VERSION ""

NS_ :

BS_:

BU_: NJX Third_Party VCU

BO_ 3221225472 VECTOR__INDEPENDENT_SIG_MSG: 0 Vector__XXX
 SG_ DEBUG_zero_suspension_travel : 0|1@1+ (1,0) [0|1] "" Vector__XXX
 SG_ SMU_BTN_external_tsa_btn_presse : 0|1@1+ (1,0) [0|1] "" Vector__XXX
 SG_ SMU_BTN_ami_btn_pressed : 0|1@1+ (1,0) [0|1] "" Vector__XXX
 SG_ SMU_BTN_rst_btn_pressed : 0|1@1+ (1,0) [0|1] "" Vector__XXX
 SG_ TSCD_K6_closed : 0|1@1+ (1,0) [0|1] "" Vector__XXX
 SG_ TSCD_SDC_active : 0|1@1+ (1,0) [0|1] "" Vector__XXX
 SG_ TSCD_SDC_in : 0|1@1+ (1,0) [0|1] "" Vector__XXX
 SG_ TSCD_TS_off : 0|1@1+ (1,0) [0|1] "" Vector__XXX
 SG_ TSCD_air_neg_closed : 0|1@1+ (1,0) [0|1] "" Vector__XXX
 SG_ TSCD_air_pos_closed : 0|1@1+ (1,0) [0|1] "" Vector__XXX
 SG_ TSCD_precharge_finished : 0|1@1+ (1,0) [0|1] "" Vector__XXX
 SG_ TSCD_precharge_relay_closed : 0|1@1+ (1,0) [0|1] "" Vector__XXX
 SG_ VCU_NM_all_active : 0|1@1+ (1,0) [0|1] "" Vector__XXX
 SG_ AMS_error_batt_cv_ct_init : 0|1@1+ (1,0) [0|1] "" Vector__XXX
 SG_ AMS_error_batt_iso_meas_monitor : 0|1@1+ (1,0) [0|1] "" Vector__XXX
 SG_ AMS_error_batt_vit_init : 0|1@1+ (1,0) [0|1] "" Vector__XXX
 SG_ AMS_error_bms_init_1 : 0|1@1+ (1,0) [0|1] "" Vector__XXX
 SG_ AMS_error_bms_init_2 : 0|1@1+ (1,0) [0|1] "" Vector__XXX
 SG_ AMS_error_bms_init_3 : 0|1@1+ (1,0) [0|1] "" Vector__XXX
 SG_ AMS_error_can_init : 0|1@1+ (1,0) [0|1] "" Vector__XXX
 SG_ AMS_error_current_init : 0|1@1+ (1,0) [0|1] "" Vector__XXX
 SG_ AMS_error_cv_ct_rx_monitor : 0|1@1+ (1,0) [0|1] "" Vector__XXX
 SG_ AMS_error_eeprom_rd : 0|1@1+ (1,0) [0|1] "" Vector__XXX
 SG_ AMS_error_eeprom_wr : 0|1@1+ (1,0) [0|1] "" Vector__XXX
 SG_ AMS_error_eio1 : 0|1@1+ (1,0) [0|1] "" Vector__XXX
 SG_ AMS_error_eio2 : 0|1@1+ (1,0) [0|1] "" Vector__XXX
 SG_ AMS_error_fan : 0|1@1+ (1,0) [0|1] "" Vector__XXX
 SG_ AMS_error_lim_cell_minmax_volt : 0|1@1+ (1,0) [0|1] "" Vector__XXX
 SG_ AMS_error_lim_current_1_cont : 0|1@1+ (1,0) [0|1] "" Vector__XXX
 SG_ AMS_error_lim_current_1_max : 0|1@1+ (1,0) [0|1] "" Vector__XXX
 SG_ AMS_error_lim_current_1_pulse : 0|1@1+ (1,0) [0|1] "" Vector__XXX
 SG_ AMS_error_lim_current_2_cont : 0|1@1+ (1,0) [0|1] "" Vector__XXX
 SG_ AMS_error_lim_iso : 0|1@1+ (1,0) [0|1] "" Vector__XXX
 SG_ AMS_error_lim_soc : 0|1@1+ (1,0) [0|1] "" Vector__XXX
 SG_ AMS_error_lim_temp : 0|1@1+ (1,0) [0|1] "" Vector__XXX
 SG_ AMS_error_lim_volt : 0|1@1+ (1,0) [0|1] "" Vector__XXX
 SG_ AMS_error_lim_volt_ext : 0|1@1+ (1,0) [0|1] "" Vector__XXX
 SG_ AMS_error_not_ready : 0|1@1+ (1,0) [0|1] "" Vector__XXX
 SG_ AMS_general_error : 0|1@1+ (1,0) [0|1] "" Vector__XXX
 SG_ AMS_mcu_error : 0|1@1+ (1,0) [0|1] "" Vector__XXX
 SG_ AMS_plaus_error : 0|1@1+ (1,0) [0|1] "" Vector__XXX
 SG_ AMS_realtime_error : 0|1@1+ (1,0) [0|1] "" Vector__XXX
 SG_ AMS_soc : 0|16@1+ (0.01,0) [0|655.35] "%" Vector__XXX
 SG_ SMU_BTN_ami_btn_pressed : 0|1@1+ (1,0) [0|1] "" Vector__XXX
 SG_ SMU_BTN_external_tsa_btn_presse : 0|1@1+ (1,0) [0|1] "" Vector__XXX
 SG_ SMU_BTN_general_error : 0|1@1+ (1,0) [0|1] "" Vector__XXX
 SG_ SMU_BTN_mcu_error : 0|1@1+ (1,0) [0|1] "" Vector__XXX
 SG_ SMU_BTN_plaus_error : 0|1@1+ (1,0) [0|1] "" Vector__XXX
 SG_ SMU_BTN_realtime_error : 0|1@1+ (1,0) [0|1] "" Vector__XXX
 SG_ SMU_BTN_rst_btn_pressed : 0|1@1+ (1,0) [0|1] "" Vector__XXX
 SG_ TSCD_general_error : 0|1@1+ (1,0) [0|1] "" Vector__XXX
 SG_ TSCD_mcu_error : 0|1@1+ (1,0) [0|1] "" Vector__XXX
 SG_ TSCD_plaus_error : 0|1@1+ (1,0) [0|1] "" Vector__XXX
 SG_ TSCD_realtime_error : 0|1@1+ (1,0) [0|1] "" Vector__XXX
 SG_ ISU_AMS_ok : 0|1@1+ (1,0) [0|0] "" Vector__XXX
 SG_ ISU_IMD_ok : 0|1@1+ (1,0) [0|0] "" Vector__XXX
 SG_ ISU_general_error : 0|1@1+ (1,0) [0|1] "" Vector__XXX
 SG_ ISU_mcu_error : 0|1@1+ (1,0) [0|1] "" Vector__XXX
 SG_ ISU_plaus_error : 0|1@1+ (1,0) [0|1] "" Vector__XXX
 SG_ ISU_realtime_error : 0|1@1+ (1,0) [0|1] "" Vector__XXX
 SG_ AMS_i_battery : 0|16@1- (0.01,0) [-327.68|327.67] "A" Vector__XXX
 SG_ AMS_u_battery : 0|16@1+ (0.01,0) [0|655.35] "V" Vector__XXX
 SG_ AMS_temp_avg_stack_1 : 0|8@1+ (0.5,0) [0|127.5] "°C" Vector__XXX
 SG_ AMS_temp_avg_stack_2 : 0|8@1+ (0.5,0) [0|127.5] "°C" Vector__XXX
 SG_ AMS_temp_avg_stack_3 : 0|8@1+ (0.5,0) [0|127.5] "°C" Vector__XXX
 SG_ AMS_temp_avg_stack_4 : 0|8@1+ (0.5,0) [0|127.5] "°C" Vector__XXX
 SG_ AMS_temp_max_stack_1 : 0|8@1+ (0.5,0) [0|127.5] "°C" Vector__XXX
 SG_ AMS_temp_max_stack_2 : 0|8@1+ (0.5,0) [0|127.5] "°C" Vector__XXX
 SG_ AMS_temp_max_stack_3 : 0|8@1+ (0.5,0) [0|127.5] "°C" Vector__XXX
 SG_ AMS_temp_max_stack_4 : 0|8@1+ (0.5,0) [0|127.5] "°C" Vector__XXX
 SG_ AMS_temp_avg_stack_5 : 0|8@1+ (0.5,0) [0|127.5] "°C" Vector__XXX
 SG_ AMS_temp_avg_stack_6 : 0|8@1+ (0.5,0) [0|127.5] "°C" Vector__XXX
 SG_ AMS_temp_avg_stack_7 : 0|8@1+ (0.5,0) [0|127.5] "°C" Vector__XXX
 SG_ AMS_temp_avg_stack_8 : 0|8@1+ (0.5,0) [0|127.5] "°C" Vector__XXX
 SG_ AMS_temp_max_stack_5 : 0|8@1+ (0.5,0) [0|127.5] "°C" Vector__XXX
 SG_ AMS_temp_max_stack_6 : 0|8@1+ (0.5,0) [0|127.5] "°C" Vector__XXX
 SG_ AMS_temp_max_stack_7 : 0|8@1+ (0.5,0) [0|127.5] "°C" Vector__XXX
 SG_ AMS_temp_max_stack_8 : 0|8@1+ (0.5,0) [0|127.5] "°C" Vector__XXX
 SG_ AMS_temp_avg_stack_10 : 0|8@1+ (0.5,0) [0|127.5] "°C" Vector__XXX
 SG_ AMS_temp_avg_stack_11 : 0|8@1+ (0.5,0) [0|127.5] "°C" Vector__XXX
 SG_ AMS_temp_avg_stack_12 : 0|8@1+ (0.5,0) [0|127.5] "°C" Vector__XXX
 SG_ AMS_temp_avg_stack_9 : 0|8@1+ (0.5,0) [0|127.5] "°C" Vector__XXX
 SG_ AMS_temp_max_stack_10 : 0|8@1+ (0.5,0) [0|127.5] "°C" Vector__XXX
 SG_ AMS_temp_max_stack_11 : 0|8@1+ (0.5,0) [0|127.5] "°C" Vector__XXX
 SG_ AMS_temp_max_stack_12 : 0|8@1+ (0.5,0) [0|127.5] "°C" Vector__XXX
 SG_ AMS_temp_max_stack_9 : 0|8@1+ (0.5,0) [0|127.5] "°C" Vector__XXX
 SG_ TSCD_VBAT : 0|16@1+ (0.01,0) [0|655.35] "V" Vector__XXX
 SG_ TSCD_VINT : 0|16@1+ (0.01,0) [0|655.35] "V" Vector__XXX
 SG_ TSCD_VPRE : 0|16@1+ (0.01,0) [0|655.35] "V" Vector__XXX
 SG_ TSCD_precharge_to_ubat : 0|8@1+ (1,0) [0|255] "%" Vector__XXX
 SG_ AngSPoi : 0|16@1- (0.003,0) [-39.999|39.999] "ï¿½" Vector__XXX
 SG_ VelAPoi : 0|16@1- (0.02,0) [0|450] "km/h" Vector__XXX
 SG_ VelXPoi : 0|16@1- (0.02,0) [-450|450] "km/h" Vector__XXX
 SG_ VelYPoi : 0|16@1- (0.02,0) [-100|100] "km/h" Vector__XXX
 SG_ AccCPoi : 0|16@1- (0.02,0) [-40|40] "m/s^2" Vector__XXX
 SG_ DistAPoi : 0|32@1- (0.001,0) [-2000000|2000000] "m" Vector__XXX
 SG_ RadiusPoi : 0|16@1- (0.01,0) [-327.68|327.67] "m" Vector__XXX
 SG_ Pitch : 0|16@1- (0.003,0) [-90|90] "ï¿½" Vector__XXX
 SG_ Roll : 0|16@1- (0.003,0) [-90|90] "ï¿½" Vector__XXX
 SG_ AccXHor : 0|16@1- (0.02,0) [-655.36|655.34] "m/s^2" Vector__XXX
 SG_ AccYHor : 0|16@1- (0.02,0) [-655.36|655.34] "m/s^2" Vector__XXX
 SG_ AccZHor : 0|16@1- (0.02,0) [-655.36|655.34] "m/s^2" Vector__XXX
 SG_ RateXHor : 0|16@1- (0.02,0) [-655.36|655.34] "ï¿½/s" Vector__XXX
 SG_ RateYHor : 0|16@1- (0.02,0) [-655.36|655.34] "ï¿½/s" Vector__XXX
 SG_ RateZHor : 0|16@1- (0.02,0) [-655.36|655.34] "ï¿½/s" Vector__XXX
 SG_ AngS : 0|16@1- (0.003,0) [-39.999|39.999] "ï¿½" Vector__XXX
 SG_ VelA : 0|16@1- (0.02,0) [0|450] "km/h" Vector__XXX
 SG_ VelX : 0|16@1- (0.02,0) [-450|450] "km/h" Vector__XXX
 SG_ VelY : 0|16@1- (0.02,0) [-100|100] "km/h" Vector__XXX
 SG_ AccC : 0|16@1- (0.02,0) [-40|40] "m/s^2" Vector__XXX
 SG_ DistA : 0|32@1- (0.001,0) [-2000000|2000000] "m" Vector__XXX
 SG_ Radius : 0|16@1- (0.01,0) [-327.68|327.67] "m" Vector__XXX
 SG_ AccX : 0|16@1- (0.02,0) [-655.36|655.34] "m/s^2" Vector__XXX
 SG_ AccY : 0|16@1- (0.02,0) [-655.36|655.34] "m/s^2" Vector__XXX
 SG_ AccZ : 0|16@1- (0.02,0) [-655.36|655.34] "m/s^2" Vector__XXX
 SG_ RateX : 0|16@1- (0.02,0) [-655.36|655.34] "ï¿½/s" Vector__XXX
 SG_ RateY : 0|16@1- (0.02,0) [-655.36|655.34] "ï¿½/s" Vector__XXX
 SG_ RateZ : 0|16@1- (0.02,0) [-655.36|655.34] "ï¿½/s" Vector__XXX
 SG_ AngSSp : 0|16@1- (0.003,0) [-39.999|39.999] "ï¿½" Vector__XXX
 SG_ QualityCh0 : 0|16@1+ (1,0) [0|65535] "" Vector__XXX
 SG_ QualityCh1 : 0|16@1+ (1,0) [0|65535] "" Vector__XXX
 SG_ VelASp : 0|16@1- (0.02,0) [0|450] "km/h" Vector__XXX
 SG_ DistASp : 0|32@1- (0.001,0) [-2000000|2000000] "m" Vector__XXX
 SG_ VelXSp : 0|16@1- (0.02,0) [-450|450] "km/h" Vector__XXX
 SG_ VelYSp : 0|16@1- (0.02,0) [-100|100] "km/h" Vector__XXX
 SG_ AdjustmentActive : 0|1@1+ (1,0) [0|1] "" Vector__XXX
 SG_ CanAngAdjFailed : 0|1@1+ (1,0) [0|1] "" Vector__XXX
 SG_ DirectionNeg : 0|1@1+ (1,0) [0|1] "" Vector__XXX
 SG_ IlluOk : 0|1@1+ (1,0) [0|1] "" Vector__XXX
 SG_ IlluOn : 0|1@1+ (1,0) [0|1] "" Vector__XXX
 SG_ RateAdjustActive : 0|1@1+ (1,0) [0|1] "" Vector__XXX
 SG_ SampleTime : 0|24@1+ (0.001,0) [0|16777.215] "s" Vector__XXX
 SG_ SensorConnected : 0|1@1+ (1,0) [0|1] "" Vector__XXX
 SG_ Standstill : 0|1@1+ (1,0) [0|1] "" Vector__XXX
 SG_ StatusOk : 0|1@1+ (1,0) [0|1] "" Vector__XXX
 SG_ TempSensor : 0|16@1- (0.1,0) [-20|85] "ï¿½C" Vector__XXX
 SG_ Trigger : 0|1@1+ (1,0) [0|1] "" Vector__XXX
 SG_ InfoError : 0|1@1+ (1,0) [0|1] "" Vector__XXX
 SG_ InfoIlluIncomp : 0|1@1+ (1,0) [0|1] "" Vector__XXX
 SG_ InfoInverseMounting : 0|1@1+ (1,0) [0|1] "" Vector__XXX
 SG_ InfoMovAvgActive : 0|1@1+ (1,0) [0|1] "" Vector__XXX
 SG_ InfoPoi : 0|1@1+ (1,0) [0|1] "" Vector__XXX
 SG_ InfoServiceMode : 0|1@1+ (1,0) [0|1] "" Vector__XXX
 SG_ InfoTransversal : 0|1@1+ (1,0) [0|1] "" Vector__XXX
 SG_ LastErrorCode : 0|16@1+ (1,0) [0|65535] "" Vector__XXX
 SG_ TempProcessor : 0|8@1- (1,0) [-128|127] "ï¿½C" Vector__XXX
 SG_ FwVersion : 0|24@1+ (1,0) [0|16777215] "" Vector__XXX
 SG_ ParamSetLoaded : 0|8@1+ (1,0) [0|255] "" Vector__XXX
 SG_ SerialEcu : 0|16@1+ (1,0) [0|65535] "" Vector__XXX
 SG_ SerialSensor : 0|16@1+ (1,0) [0|65535] "" Vector__XXX

BO_ 0 VCU_CAN2_nmt_node_control: 2 VCU
 SG_ VCU_nmt_control_requested_state : 0|8@1+ (1,0) [0|255] ""  Third_Party
 SG_ VCU_nmt_node_id : 8|8@1- (1,0) [0|0] ""  Third_Party

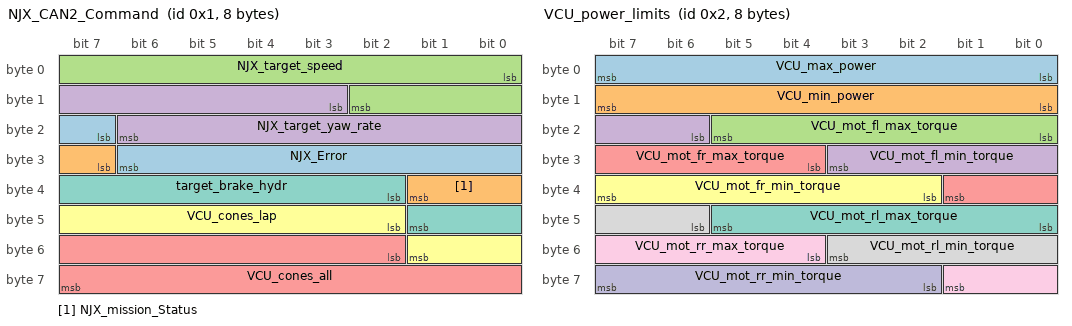
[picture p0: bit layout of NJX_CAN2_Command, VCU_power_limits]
BO_ 1 NJX_CAN2_Command: 8 Third_Party
 SG_ NJX_Error : 23|8@1+ (1,0) [0|255] ""  VCU
 SG_ NJX_mission_Status : 31|3@1+ (1,0) [0|7] ""  VCU
 SG_ NJX_target_speed : 0|11@1+ (0.02,0) [0|40.94] "m/s"  VCU
 SG_ NJX_target_yaw_rate : 11|12@1- (0.002,0) [-4.096|4.094] "rad/s"  VCU
 SG_ VCU_cones_all : 50|14@1+ (1,0) [0|16383] ""  VCU
 SG_ VCU_cones_lap : 42|8@1+ (1,0) [0|255] ""  VCU
 SG_ target_brake_hydr : 34|8@1+ (0.5,0) [0|127.5] "%"  VCU

BO_ 2 VCU_power_limits: 8 VCU
 SG_ VCU_max_power : 0|8@1- (1000,0) [-128000|127000] "" Vector__XXX
 SG_ VCU_min_power : 8|8@1- (1000,0) [-128000|127000] "" Vector__XXX
 SG_ VCU_mot_fl_max_torque : 16|6@1+ (1,0) [0|63] "Nm" Vector__XXX
 SG_ VCU_mot_fl_min_torque : 22|6@1+ (1,-63) [-63|0] "Nm" Vector__XXX
 SG_ VCU_mot_fr_max_torque : 28|6@1+ (1,0) [0|63] "Nm" Vector__XXX
 SG_ VCU_mot_fr_min_torque : 34|6@1+ (1,-63) [-63|0] "Nm" Vector__XXX
 SG_ VCU_mot_rl_max_torque : 40|6@1+ (1,0) [0|63] "Nm" Vector__XXX
 SG_ VCU_mot_rl_min_torque : 46|6@1+ (1,-63) [-63|0] "Nm" Vector__XXX
 SG_ VCU_mot_rr_max_torque : 52|6@1+ (1,0) [0|63] "Nm" Vector__XXX
 SG_ VCU_mot_rr_min_torque : 58|6@1+ (1,-63) [-63|0] "Nm" Vector__XXX

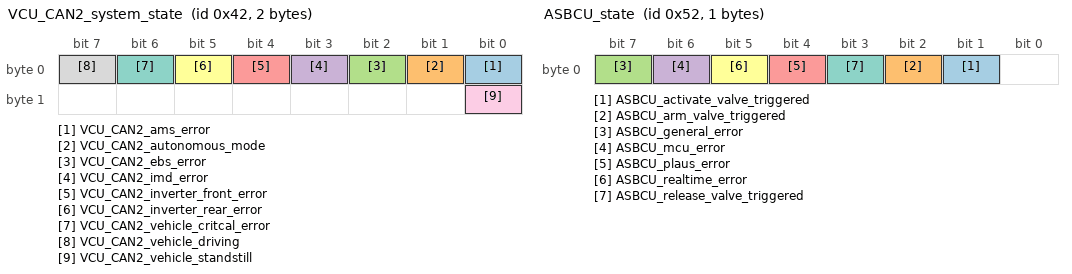
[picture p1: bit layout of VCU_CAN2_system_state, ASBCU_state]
BO_ 66 VCU_CAN2_system_state: 2 VCU
 SG_ VCU_CAN2_ams_error : 0|1@1+ (1,0) [0|1] ""  Third_Party
 SG_ VCU_CAN2_autonomous_mode : 1|1@1+ (1,0) [0|1] ""  Third_Party
 SG_ VCU_CAN2_ebs_error : 2|1@1+ (1,0) [0|1] ""  Third_Party
 SG_ VCU_CAN2_imd_error : 3|1@1+ (1,0) [0|1] ""  Third_Party
 SG_ VCU_CAN2_inverter_front_error : 4|1@1+ (1,0) [0|1] ""  Third_Party
 SG_ VCU_CAN2_inverter_rear_error : 5|1@1+ (1,0) [0|1] ""  Third_Party
 SG_ VCU_CAN2_vehicle_critcal_error : 6|1@1+ (1,0) [0|1] ""  Third_Party
 SG_ VCU_CAN2_vehicle_driving : 7|1@1+ (1,0) [0|1] ""  Third_Party
 SG_ VCU_CAN2_vehicle_standstill : 8|1@1+ (1,0) [0|1] ""  Third_Party

BO_ 82 ASBCU_state: 1 Third_Party
 SG_ ASBCU_activate_valve_triggered : 1|1@1+ (1,0) [0|1] ""  VCU
 SG_ ASBCU_arm_valve_triggered : 2|1@1+ (1,0) [0|1] ""  VCU
 SG_ ASBCU_general_error : 7|1@1+ (1,0) [0|1] ""  VCU
 SG_ ASBCU_mcu_error : 6|1@1+ (1,0) [0|1] ""  VCU
 SG_ ASBCU_plaus_error : 4|1@1+ (1,0) [0|1] ""  VCU
 SG_ ASBCU_realtime_error : 5|1@1+ (1,0) [0|1] ""  VCU
 SG_ ASBCU_release_valve_triggered : 3|1@1+ (1,0) [0|1] ""  VCU

BO_ 86 VCU_CAN2_ASI_state: 1 VCU
 SG_ ASI_Status : 0|8@1+ (1,0) [0|255] ""  Third_Party

BO_ 90 GL2010_CAN2_state: 2 Third_Party
 SG_ GL2010_CAN2_dummy : 0|16@1- (1,0) [0|0] ""  VCU

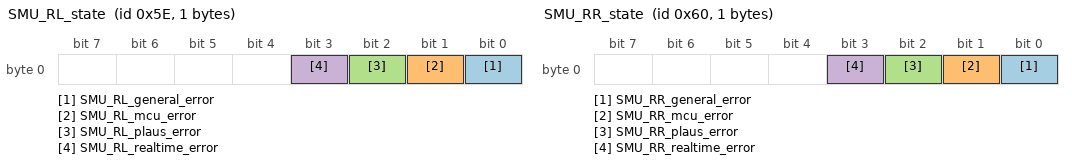
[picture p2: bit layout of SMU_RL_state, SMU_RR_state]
BO_ 94 SMU_RL_state: 1 Third_Party
 SG_ SMU_RL_general_error : 0|1@1+ (1,0) [0|1] ""  VCU
 SG_ SMU_RL_mcu_error : 1|1@1+ (1,0) [0|1] ""  VCU
 SG_ SMU_RL_plaus_error : 2|1@1+ (1,0) [0|1] ""  VCU
 SG_ SMU_RL_realtime_error : 3|1@1+ (1,0) [0|1] ""  VCU

BO_ 96 SMU_RR_state: 1 Third_Party
 SG_ SMU_RR_general_error : 0|1@1+ (1,0) [0|1] ""  VCU
 SG_ SMU_RR_mcu_error : 1|1@1+ (1,0) [0|1] ""  VCU
 SG_ SMU_RR_plaus_error : 2|1@1+ (1,0) [0|1] ""  VCU
 SG_ SMU_RR_realtime_error : 3|1@1+ (1,0) [0|1] ""  VCU

BO_ 128 RES_reserved_sync: 8 Third_Party
 SG_ RES_dummy : 0|64@1- (1,0) [0|0] ""  VCU

BO_ 145 RES_emergency: 8 Third_Party
 SG_ RES_dummy : 0|64@1- (1,0) [0|0] ""  VCU

BO_ 256 RES_reserved_timestamp: 8 Third_Party
 SG_ RES_dummy : 0|64@1- (1,0) [0|0] ""  VCU

BO_ 322 VCU_CAN2_vehicle_state: 7 VCU
 SG_ AMS_general_error : 16|1@1+ (1,0) [0|1] ""  Third_Party
 SG_ VCU_FS_Logger_Status : 13|1@1+ (1,0) [0|1] ""  Third_Party
 SG_ VCU_LC_state : 20|2@1+ (1,0) [0|3] ""  Third_Party
 SG_ VCU_RES_status : 17|3@1+ (1,0) [0|7] ""  Third_Party
 SG_ VCU_VelEstMode : 10|2@1+ (1,0) [0|3] ""  Third_Party
 SG_ VCU_apps_error : 0|1@1+ (1,0) [0|1] ""  Third_Party
 SG_ VCU_bl_active : 14|1@1+ (1,0) [0|1] ""  Third_Party
 SG_ VCU_bpps_error : 1|1@1+ (1,0) [0|1] ""  Third_Party
 SG_ VCU_bps_error : 2|1@1+ (1,0) [0|1] ""  Third_Party
 SG_ VCU_fan_l_error : 22|1@1+ (1,0) [0|1] ""  Third_Party
 SG_ VCU_fan_r_error : 23|1@1+ (1,0) [0|1] ""  Third_Party
 SG_ VCU_fan_rl_speed : 36|6@1+ (1.5873016,0) [0|100.0000008] "%"  Third_Party
 SG_ VCU_fan_rr_speed : 42|6@1+ (1.5873016,0) [0|100.0000008] ""  Third_Party
 SG_ VCU_pump_l_error : 8|1@1+ (1,0) [0|1] ""  Third_Party
 SG_ VCU_pump_r_error : 9|1@1+ (1,0) [0|1] ""  Third_Party
 SG_ VCU_pump_rl_speed : 24|6@1+ (1.5873016,0) [0|100.0000008] ""  Third_Party
 SG_ VCU_pump_rr_speed : 30|6@1+ (1.5873016,0) [0|100.0000008] ""  Third_Party
 SG_ VCU_ready_for_rtd : 7|1@1+ (1,0) [0|1] ""  Third_Party
 SG_ VCU_ready_for_tsa : 6|1@1+ (1,0) [0|1] ""  Third_Party
 SG_ VCU_rtd : 5|1@1+ (1,0) [0|1] ""  Third_Party
 SG_ VCU_rtds_active : 15|1@1+ (1,0) [0|1] ""  Third_Party
 SG_ VCU_torque_alloc_error : 12|1@1+ (1,0) [0|1] ""  Third_Party
 SG_ VCU_tsa : 4|1@1+ (1,0) [0|1] ""  Third_Party
 SG_ VCU_vehicle_error : 3|1@1+ (1,0) [0|1] ""  Third_Party

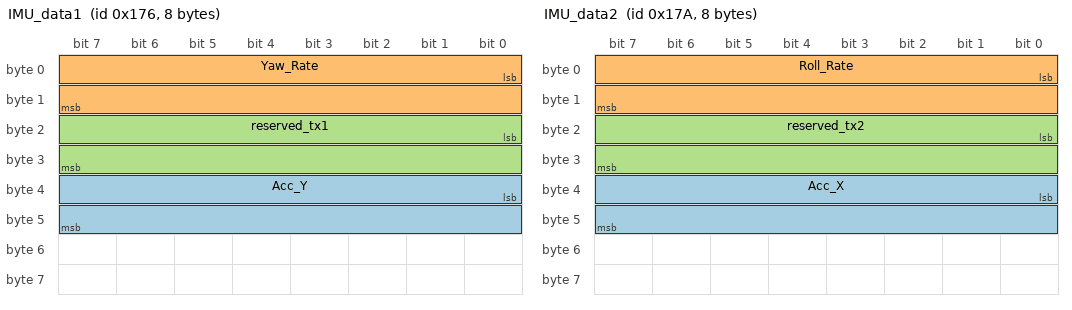
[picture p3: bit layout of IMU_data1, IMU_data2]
BO_ 374 IMU_data1: 8 Third_Party
 SG_ Acc_Y : 32|16@1+ (0.001249794,-40.953249792) [-40.953249792|40.951999998] "m/s²"  VCU
 SG_ Yaw_Rate : 0|16@1+ (0.005,-163.84) [-163.84|163.835] "°/s"  VCU
 SG_ reserved_tx1 : 16|16@1- (1,0) [0|0] ""  VCU

BO_ 378 IMU_data2: 8 Third_Party
 SG_ Acc_X : 32|16@1+ (0.001249794,-40.953249792) [-40.953249792|40.951999998] "m/s²"  VCU
 SG_ Roll_Rate : 0|16@1+ (0.005,-163.48) [-163.48|164.195] "°/s"  VCU
 SG_ reserved_tx2 : 16|16@1- (1,0) [0|0] ""  VCU

BO_ 382 IMU_data3: 8 Third_Party
 SG_ Acc_Z : 32|16@1+ (0.001249794,-40.953249792) [-40.953249792|40.951999998] "m/s²"  VCU
 SG_ reserved_tx3 : 0|16@1- (1,0) [0|0] ""  VCU

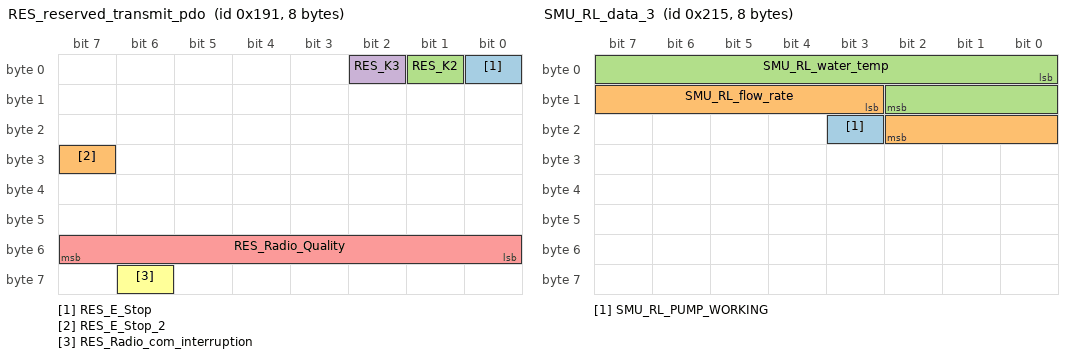
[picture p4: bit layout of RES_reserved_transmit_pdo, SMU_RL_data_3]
BO_ 401 RES_reserved_transmit_pdo: 8 Third_Party
 SG_ RES_E_Stop : 0|1@1+ (1,0) [0|1] ""  VCU
 SG_ RES_E_Stop_2 : 31|1@1+ (1,0) [0|1] ""  VCU
 SG_ RES_K2 : 1|1@1+ (1,0) [0|1] ""  VCU
 SG_ RES_K3 : 2|1@1+ (1,0) [0|1] ""  VCU
 SG_ RES_Radio_Quality : 48|8@1- (1,0) [-128|127] "%"  VCU
 SG_ RES_Radio_com_interruption : 62|1@1+ (1,0) [0|1] ""  VCU

BO_ 528 SMU_RL_data_1: 2 Third_Party
 SG_ SMU_RL_suspension_travel : 0|16@1- (0.01,0) [-327.68|327.67] "mm"  VCU

BO_ 529 RES_reserved_receive_pdo: 8 Third_Party
 SG_ RES_dummy : 0|64@1- (1,0) [0|0] ""  VCU

BO_ 530 SMU_RL_data_2: 2 Third_Party
 SG_ SMU_RL_gear_temp : 0|8@1+ (0.5,0) [0|127.5] "°C"  VCU
 SG_ SMU_RL_motor_temp : 8|8@1+ (0.5,0) [0|127.5] "°C"  VCU

BO_ 532 SMU_RR_data_1: 2 Third_Party
 SG_ SMU_RR_suspension_travel : 0|16@1- (0.01,0) [-327.68|327.67] "mm"  VCU

BO_ 533 SMU_RL_data_3: 8 Third_Party
 SG_ SMU_RL_PUMP_WORKING : 19|1@1+ (1,0) [0|1] ""  VCU
 SG_ SMU_RL_flow_rate : 11|8@1+ (0.1,0) [0|25.5] ""  VCU
 SG_ SMU_RL_water_temp : 0|11@1+ (0.1,0) [0|204.7] "Â°C"  VCU

BO_ 534 SMU_RR_data_2: 2 Third_Party
 SG_ SMU_RR_gear_temp : 0|8@1+ (0.5,0) [0|127.5] "°C"  VCU
 SG_ SMU_RR_motor_temp : 8|8@1+ (0.5,0) [0|127.5] "°C"  VCU

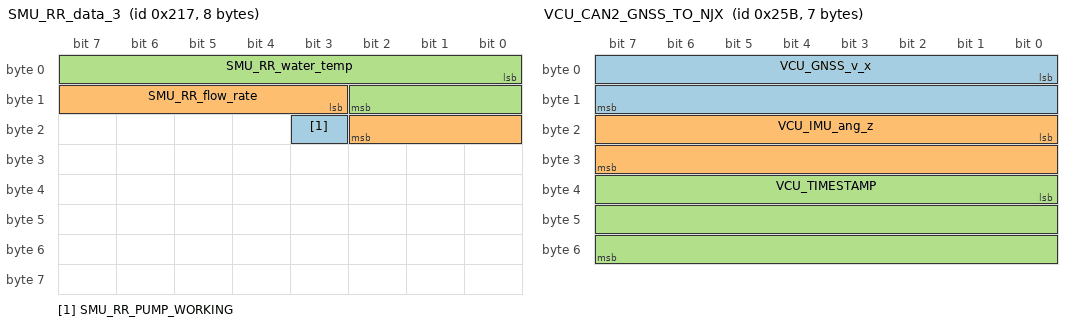
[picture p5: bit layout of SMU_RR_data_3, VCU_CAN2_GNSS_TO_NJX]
BO_ 535 SMU_RR_data_3: 8 Third_Party
 SG_ SMU_RR_PUMP_WORKING : 19|1@1+ (1,0) [0|1] ""  VCU
 SG_ SMU_RR_flow_rate : 11|8@1+ (0.1,0) [0|25.5] ""  VCU
 SG_ SMU_RR_water_temp : 0|11@1+ (0.1,0) [0|204.7] "Â°C"  VCU

BO_ 544 ASBCU_data: 2 Third_Party
 SG_ ASBCU_activated_sensor : 0|8@1+ (0.1,0) [0|25.5] "bar"  VCU
 SG_ ASBCU_armed_sensor : 8|8@1+ (0.1,0) [0|25.5] "bar"  VCU

BO_ 603 VCU_CAN2_GNSS_TO_NJX: 7 VCU
 SG_ VCU_GNSS_v_x : 0|16@1+ (0.0009765625,0) [0|63.9990234375] "m/s"  Third_Party
 SG_ VCU_IMU_ang_z : 16|16@1- (0.015625,0) [-512|511.984375] "rad/s"  Third_Party
 SG_ VCU_TIMESTAMP : 32|24@1+ (0.005,0) [0|83886.075] "s"  Third_Party

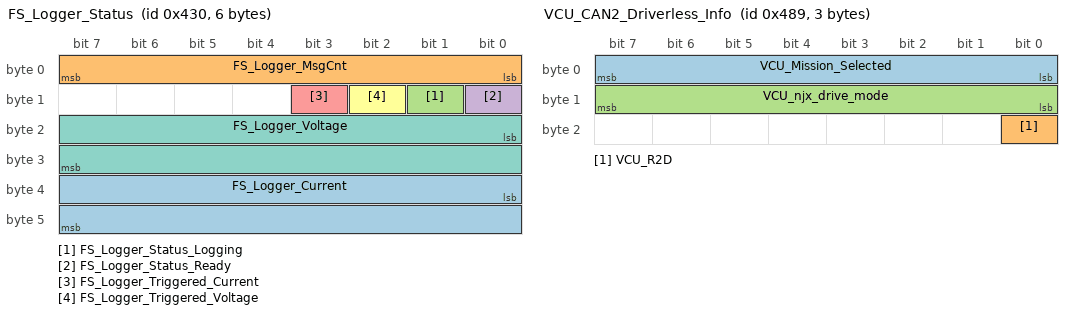
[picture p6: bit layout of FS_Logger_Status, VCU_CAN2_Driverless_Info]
BO_ 1072 FS_Logger_Status: 6 Third_Party
 SG_ FS_Logger_Current : 32|16@1+ (64,0) [0|4194240] "mA"  VCU
 SG_ FS_Logger_MsgCnt : 0|8@1+ (1,0) [0|255] ""  VCU
 SG_ FS_Logger_Status_Logging : 9|1@1+ (1,0) [0|1] ""  VCU
 SG_ FS_Logger_Status_Ready : 8|1@1+ (1,0) [0|1] ""  VCU
 SG_ FS_Logger_Triggered_Current : 11|1@1+ (1,0) [0|1] ""  VCU
 SG_ FS_Logger_Triggered_Voltage : 10|1@1+ (1,0) [0|1] ""  VCU
 SG_ FS_Logger_Voltage : 16|16@1+ (16,0) [0|1048560] "mV"  VCU

BO_ 1161 VCU_CAN2_Driverless_Info: 3 VCU
 SG_ VCU_Mission_Selected : 0|8@1+ (1,0) [0|255] "" Vector__XXX
 SG_ VCU_R2D : 16|1@1+ (1,0) [0|1] "" Vector__XXX
 SG_ VCU_njx_drive_mode : 8|8@1+ (1,0) [0|255] "" Vector__XXX

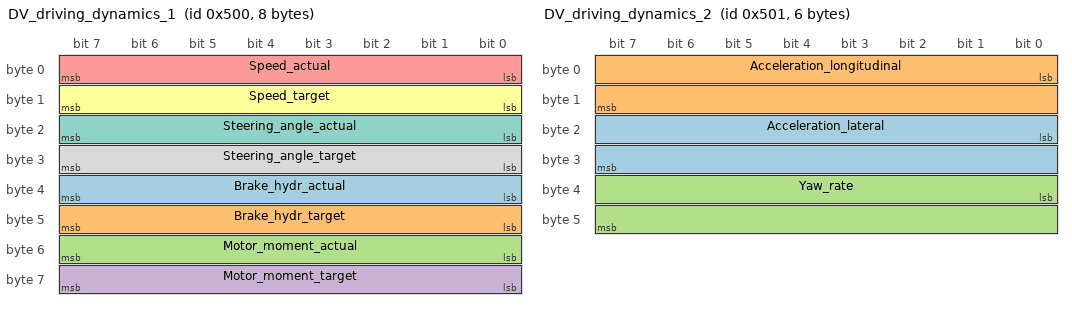
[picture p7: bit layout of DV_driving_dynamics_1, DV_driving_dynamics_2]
BO_ 1280 DV_driving_dynamics_1: 8 VCU
 SG_ Brake_hydr_actual : 32|8@1+ (1,0) [0|255] "%" Vector__XXX
 SG_ Brake_hydr_target : 40|8@1+ (1,0) [0|127] "%" Vector__XXX
 SG_ Motor_moment_actual : 48|8@1- (1,0) [-128|127] "%" Vector__XXX
 SG_ Motor_moment_target : 56|8@1- (1,0) [-128|127] "%" Vector__XXX
 SG_ Speed_actual : 0|8@1+ (1,0) [0|255] "km/h" Vector__XXX
 SG_ Speed_target : 8|8@1+ (1,0) [0|255] "km/h" Vector__XXX
 SG_ Steering_angle_actual : 16|8@1- (0.5,0) [-64|63.5] "°" Vector__XXX
 SG_ Steering_angle_target : 24|8@1- (0.5,0) [-64|63.5] "°" Vector__XXX

BO_ 1281 DV_driving_dynamics_2: 6 VCU
 SG_ Acceleration_lateral : 16|16@1- (0.001953125,0) [-64|63.998046875] "m/s²" Vector__XXX
 SG_ Acceleration_longitudinal : 0|16@1- (0.001953125,0) [-64|63.998046875] "m/s²" Vector__XXX
 SG_ Yaw_rate : 32|16@1- (0.0078125,0) [-256|255.9921875] "°/s" Vector__XXX

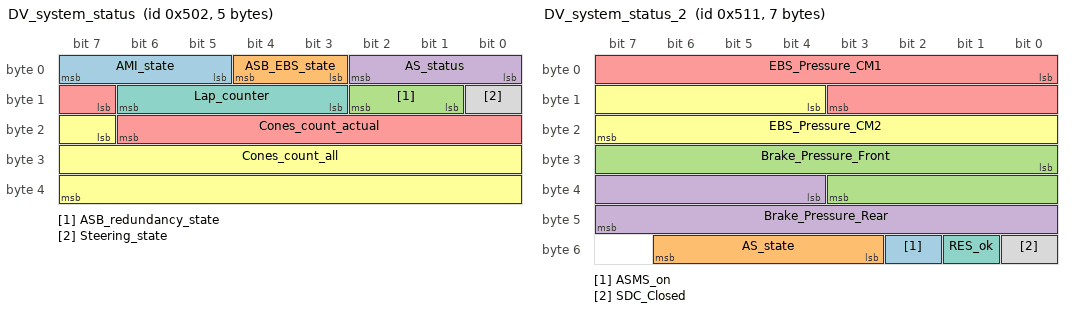
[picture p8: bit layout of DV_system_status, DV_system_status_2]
BO_ 1282 DV_system_status: 5 VCU
 SG_ AMI_state : 5|3@1+ (1,0) [0|7] "" Vector__XXX
 SG_ ASB_EBS_state : 3|2@1+ (1,0) [0|3] "" Vector__XXX
 SG_ ASB_redundancy_state : 9|2@1+ (1,0) [0|3] "" Vector__XXX
 SG_ AS_status : 0|3@1+ (1,0) [0|7] "" Vector__XXX
 SG_ Cones_count_actual : 15|8@1+ (1,0) [0|255] "" Vector__XXX
 SG_ Cones_count_all : 23|17@1+ (1,0) [0|65535] "" Vector__XXX
 SG_ Lap_counter : 11|4@1+ (1,0) [0|15] "" Vector__XXX
 SG_ Steering_state : 8|1@1+ (1,0) [0|1] "" Vector__XXX

BO_ 1297 DV_system_status_2: 7 VCU
 SG_ ASMS_on : 50|1@1+ (1,0) [0|1] "" Vector__XXX
 SG_ AS_state : 51|4@1+ (1,0) [0|15] "" Vector__XXX
 SG_ Brake_Pressure_Front : 24|12@1+ (0.1,0) [0|409.5] "bar" Vector__XXX
 SG_ Brake_Pressure_Rear : 36|12@1+ (0.1,0) [0|409.5] "bar" Vector__XXX
 SG_ EBS_Pressure_CM1 : 0|12@1+ (0.1,0) [0|409.5] "bar" Vector__XXX
 SG_ EBS_Pressure_CM2 : 12|12@1+ (0.1,0) [0|409.5] "bar" Vector__XXX
 SG_ RES_ok : 49|1@1+ (1,0) [0|1] "" Vector__XXX
 SG_ SDC_Closed : 48|1@1+ (1,0) [0|1] "" Vector__XXX

BO_ 1425 RES_reserved_transmit_sdo: 8 Third_Party
 SG_ RES_dummy : 0|64@1- (1,0) [0|0] ""  VCU

BO_ 1553 RES_reserved_receive_sdo: 8 Third_Party
 SG_ RES_dummy : 0|64@1- (1,0) [0|0] ""  VCU

BO_ 1664 CAN_Flash_RX: 8 Third_Party

BO_ 1665 CAN_Flash_SMU_RL_TX: 8 Third_Party

BO_ 1666 CAN_Flash_SMU_RR_TX: 8 Third_Party

BO_ 1667 CAN_Flash_SMU_F_TX: 8 Third_Party

BO_ 1668 CAN_Flash_SMU_PB_TX: 8 Third_Party

BO_ 1670 CAN_Flash_ASI_TX: 8 VCU

BO_ 1671 CAN_Flash_EFuse_TX: 8 VCU

BO_ 1672 CAN_Flash_DMI_TX: 8 Third_Party

BO_ 1673 CAN_Flash_SMU_AD_TX: 8 Third_Party

BO_ 1674 CAN_Flash_ASSI_ACCUCART_TX: 8 Third_Party

BO_ 1675 CAN_Flash_SMU_TESTBENCH_TX: 8 Third_Party

BO_ 1676 CAN_Flash_DCDC_ACTIVATION: 8 Third_Party

BO_ 1679 CAN_Flash_SMU_test: 8 VCU

BO_ 1809 RES_bootup: 1 Third_Party
 SG_ RES_bootup_sig : 0|8@1+ (1,0) [0|255] ""  VCU

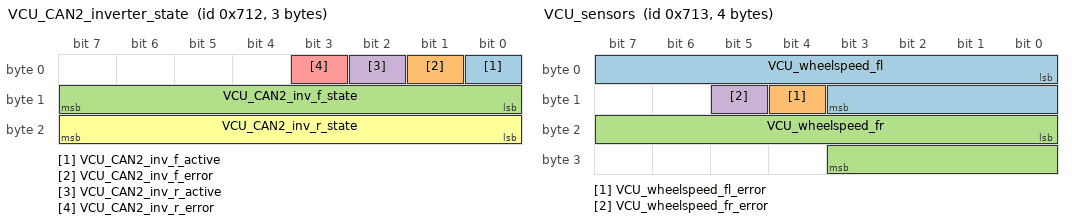
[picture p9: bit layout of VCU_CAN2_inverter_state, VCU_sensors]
BO_ 1810 VCU_CAN2_inverter_state: 3 VCU
 SG_ VCU_CAN2_inv_f_active : 0|1@1+ (1,0) [0|1] ""  Third_Party
 SG_ VCU_CAN2_inv_f_error : 1|1@1+ (1,0) [0|1] ""  Third_Party
 SG_ VCU_CAN2_inv_f_state : 8|8@1+ (1,0) [0|255] ""  Third_Party
 SG_ VCU_CAN2_inv_r_active : 2|1@1+ (1,0) [0|1] ""  Third_Party
 SG_ VCU_CAN2_inv_r_error : 3|1@1+ (1,0) [0|1] ""  Third_Party
 SG_ VCU_CAN2_inv_r_state : 16|8@1+ (1,0) [0|255] ""  Third_Party

BO_ 1811 VCU_sensors: 4 VCU
 SG_ VCU_wheelspeed_fl : 0|12@1+ (0.01,0) [0|40.95] "m/s" Vector__XXX
 SG_ VCU_wheelspeed_fl_error : 12|1@1+ (1,0) [0|1] "" Vector__XXX
 SG_ VCU_wheelspeed_fr : 16|12@1+ (0.01,0) [0|40.95] "m/s" Vector__XXX
 SG_ VCU_wheelspeed_fr_error : 13|1@1+ (1,0) [0|1] "" Vector__XXX

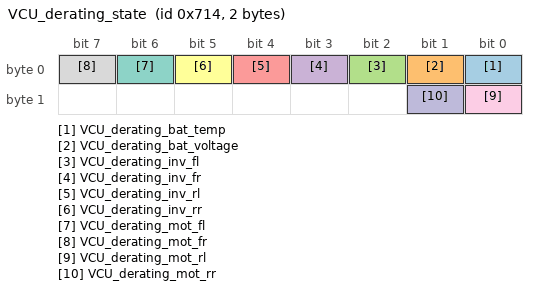
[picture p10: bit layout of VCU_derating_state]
BO_ 1812 VCU_derating_state: 2 VCU
 SG_ VCU_derating_bat_temp : 0|1@1+ (1,0) [0|1] ""  Third_Party
 SG_ VCU_derating_bat_voltage : 1|1@1+ (1,0) [0|1] ""  Third_Party
 SG_ VCU_derating_inv_fl : 2|1@1+ (1,0) [0|1] ""  Third_Party
 SG_ VCU_derating_inv_fr : 3|1@1+ (1,0) [0|1] ""  Third_Party
 SG_ VCU_derating_inv_rl : 4|1@1+ (1,0) [0|1] ""  Third_Party
 SG_ VCU_derating_inv_rr : 5|1@1+ (1,0) [0|1] ""  Third_Party
 SG_ VCU_derating_mot_fl : 6|1@1+ (1,0) [0|1] ""  Third_Party
 SG_ VCU_derating_mot_fr : 7|1@1+ (1,0) [0|1] ""  Third_Party
 SG_ VCU_derating_mot_rl : 8|1@1+ (1,0) [0|1] ""  Third_Party
 SG_ VCU_derating_mot_rr : 9|1@1+ (1,0) [0|1] ""  Third_Party

BO_ 1813 VCU_driver_request: 3 VCU
 SG_ VCU_torque_request : 0|8@1- (0.25,0) [-32|31.75] ""  Third_Party
 SG_ VCU_yaw_moment_request : 8|12@1- (1,0) [-2048|2047] ""  Third_Party

BO_ 1872 FS_Logger_Reserved_1: 0 Third_Party

BO_ 1873 FS_Logger_Reserved_2: 0 Third_Party

BO_ 1874 FS_Logger_Reserved_3: 0 Third_Party

BO_ 1875 FS_Logger_Reserved_4: 0 Third_Party

BO_ 1876 FS_Logger_Reserved_5: 0 Third_Party

BO_ 1877 FS_Logger_Reserved_6: 0 Third_Party

BO_ 2020 RES_reserved_lss_transmit: 8 Third_Party
 SG_ RES_dummy : 0|64@1- (1,0) [0|0] ""  VCU

BO_ 2021 RES_reserved_lss_receive: 8 Third_Party
 SG_ RES_dummy : 0|64@1- (1,0) [0|0] ""  VCU

CM_ BO_ 3221225472 "This is a message for not used signals, created by Vector CANdb++ DBC OLE DB Provider.";
CM_ SG_ 3221225472 SMU_BTN_external_tsa_btn_presse "Original name (from import source): SMU_BTN_external_tsa_btn_pressed";
CM_ SG_ 3221225472 SMU_BTN_external_tsa_btn_presse "Original name (from import source): SMU_BTN_external_tsa_btn_pressed";
CM_ SG_ 86 ASI_Status "0;1;2;3;4; OFF;READY;DRIVING;FINISHED;EMERGENCY";
BA_DEF_  "DBName" STRING ;
BA_DEF_ BO_  "GenMsgCycleTime" INT 0 0;
BA_DEF_ BO_  "GenMsgSendType" ENUM  "Cyclic","OnEvent";
BA_DEF_ SG_  "GenSigStartValue" INT 0 0;
BA_DEF_ SG_  "SPN" INT 0 524287;
BA_DEF_DEF_  "DBName" "";
BA_DEF_DEF_  "GenMsgCycleTime" 0;
BA_DEF_DEF_  "GenMsgSendType" "";
BA_DEF_DEF_  "GenSigStartValue" 0;
BA_DEF_DEF_  "SPN" 0;
BA_ "DBName" "CAN2";
BA_ "GenMsgSendType" BO_ 0 1;
BA_ "GenMsgSendType" BO_ 1 0;
BA_ "GenMsgSendType" BO_ 2 0;
BA_ "GenMsgSendType" BO_ 66 1;
BA_ "GenMsgSendType" BO_ 82 1;
BA_ "GenMsgSendType" BO_ 86 0;
BA_ "GenMsgSendType" BO_ 90 1;
BA_ "GenMsgSendType" BO_ 94 1;
BA_ "GenMsgSendType" BO_ 96 1;
BA_ "GenMsgSendType" BO_ 128 1;
BA_ "GenMsgSendType" BO_ 145 1;
BA_ "GenMsgSendType" BO_ 256 1;
BA_ "GenMsgSendType" BO_ 322 1;
BA_ "GenMsgSendType" BO_ 374 0;
BA_ "GenMsgSendType" BO_ 378 0;
BA_ "GenMsgSendType" BO_ 382 0;
BA_ "GenMsgSendType" BO_ 401 1;
BA_ "GenMsgSendType" BO_ 528 1;
BA_ "GenMsgSendType" BO_ 529 1;
BA_ "GenMsgSendType" BO_ 530 1;
BA_ "GenMsgSendType" BO_ 532 1;
BA_ "GenMsgSendType" BO_ 533 0;
BA_ "GenMsgSendType" BO_ 534 1;
BA_ "GenMsgSendType" BO_ 535 0;
BA_ "GenMsgSendType" BO_ 544 1;
BA_ "GenMsgSendType" BO_ 603 1;
BA_ "GenMsgSendType" BO_ 1072 1;
BA_ "GenMsgSendType" BO_ 1161 0;
BA_ "GenMsgSendType" BO_ 1280 1;
BA_ "GenMsgSendType" BO_ 1281 1;
BA_ "GenMsgSendType" BO_ 1282 1;
BA_ "GenMsgSendType" BO_ 1297 1;
BA_ "GenMsgSendType" BO_ 1425 1;
BA_ "GenMsgSendType" BO_ 1553 1;
BA_ "GenMsgSendType" BO_ 1664 1;
BA_ "GenMsgSendType" BO_ 1665 1;
BA_ "GenMsgSendType" BO_ 1666 1;
BA_ "GenMsgSendType" BO_ 1667 1;
BA_ "GenMsgSendType" BO_ 1668 1;
BA_ "GenMsgCycleTime" BO_ 1670 100;
BA_ "GenMsgSendType" BO_ 1670 0;
BA_ "GenMsgCycleTime" BO_ 1671 100;
BA_ "GenMsgSendType" BO_ 1671 0;
BA_ "GenMsgSendType" BO_ 1672 1;
BA_ "GenMsgSendType" BO_ 1673 1;
BA_ "GenMsgSendType" BO_ 1674 1;
BA_ "GenMsgSendType" BO_ 1675 1;
BA_ "GenMsgSendType" BO_ 1676 1;
BA_ "GenMsgCycleTime" BO_ 1679 100;
BA_ "GenMsgSendType" BO_ 1679 0;
BA_ "GenMsgSendType" BO_ 1809 1;
BA_ "GenMsgSendType" BO_ 1810 1;
BA_ "GenMsgCycleTime" BO_ 1811 100;
BA_ "GenMsgSendType" BO_ 1811 0;
BA_ "GenMsgSendType" BO_ 1812 1;
BA_ "GenMsgSendType" BO_ 1813 1;
BA_ "GenMsgSendType" BO_ 1872 1;
BA_ "GenMsgSendType" BO_ 1873 1;
BA_ "GenMsgSendType" BO_ 1874 1;
BA_ "GenMsgSendType" BO_ 1875 1;
BA_ "GenMsgSendType" BO_ 1876 1;
BA_ "GenMsgSendType" BO_ 1877 1;
BA_ "GenMsgSendType" BO_ 2020 1;
BA_ "GenMsgSendType" BO_ 2021 1;
